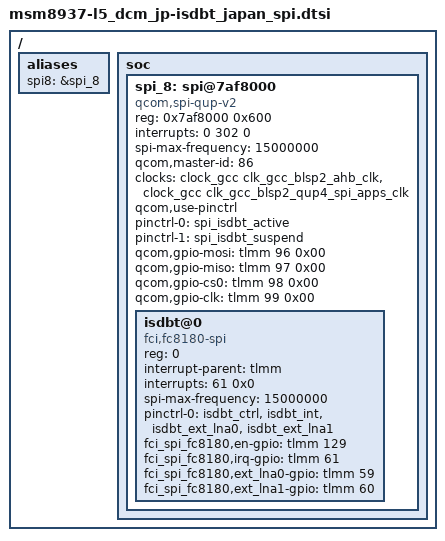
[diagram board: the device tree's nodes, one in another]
/* Copyright (c) 2014, The Linux Foundation. All rights reserved.
 *
 * This program is free software; you can redistribute it and/or modify
 * it under the terms of the GNU General Public License version 2 and
 * only version 2 as published by the Free Software Foundation.
 *
 * This program is distributed in the hope that it will be useful,
 * but WITHOUT ANY WARRANTY; without even the implied warranty of
 * MERCHANTABILITY or FITNESS FOR A PARTICULAR PURPOSE.  See the
 * GNU General Public License for more details.
 */

/ {
	aliases {
		spi8 = &spi_8;
	};

	soc {
		spi_8: spi@7af8000{    // BLSP8, BLSP-2 QUP-4
			status = "ok";
			compatible = "qcom,spi-qup-v2";

			#address-cells = <1>;
			#size-cells = <0>;

			//reg-names = "spi_physical", "spi_bam_physical";
			//reg = <0x7af8000 0x600>, <0x7AC4000 0x1f000>;
			reg-names = "spi_physical";
			reg = <0x7af8000 0x600>;

			//interrupt-names = "spi_irq", "spi_bam_irq";
			//interrupts = <0 302 0>, <0 239 0>;
			interrupt-names = "spi_irq";
			interrupts = <0 302 0>;

			spi-max-frequency = <15000000>;
			qcom,master-id = <86>;

			clock-names = "iface_clk", "core_clk";
			clocks = <&clock_gcc clk_gcc_blsp2_ahb_clk>,
				<&clock_gcc clk_gcc_blsp2_qup4_spi_apps_clk>;

			/* Assign runtime functions to pins */
			qcom,use-pinctrl;
			pinctrl-names = "spi_default","spi_sleep";
			pinctrl-0 = <&spi_isdbt_active>; // defined in msm8937-l5_dcm_jp-pinctrl.dtsi
			pinctrl-1 = <&spi_isdbt_suspend>; // defined in msm8937-l5_dcm_jp-pinctrl.dtsi

			qcom,gpio-mosi = <&tlmm 96 0x00>;
			qcom,gpio-miso = <&tlmm 97 0x00>;
			qcom,gpio-cs0 = <&tlmm 98 0x00>;
			qcom,gpio-clk = <&tlmm 99 0x00>;
			
			//qcom,infinite-mode = <0>;
			//qcom,use-bam;
			//qcom,ver-reg-exists;
			//qcom,bam-consumer-pipe-index = <18>;
			//qcom,bam-producer-pipe-index = <19>;
		};
	};
};

&spi_8 {
	isdbt@0 {
		compatible = "fci,fc8180-spi";
		reg = <0>;
		interrupt-parent = <&tlmm>;
		interrupts = <61 0x0>;
		spi-max-frequency = <15000000>;

		pinctrl-names = "isdbt_gpio"; // defined in msm8937-l5_dcm_jp-pinctrl.dtsi
		pinctrl-0 = <&isdbt_ctrl &isdbt_int &isdbt_ext_lna0 &isdbt_ext_lna1>; // defined in msm8937-l5_dcm_jp-pinctrl.dtsi
		fci_spi_fc8180,en-gpio = <&tlmm 129 0x00>;
		fci_spi_fc8180,irq-gpio = <&tlmm 61 0x00>;
                fci_spi_fc8180,ext_lna0-gpio = <&tlmm 59 0x00>;
                fci_spi_fc8180,ext_lna1-gpio = <&tlmm 60 0x00>;
	};
};
